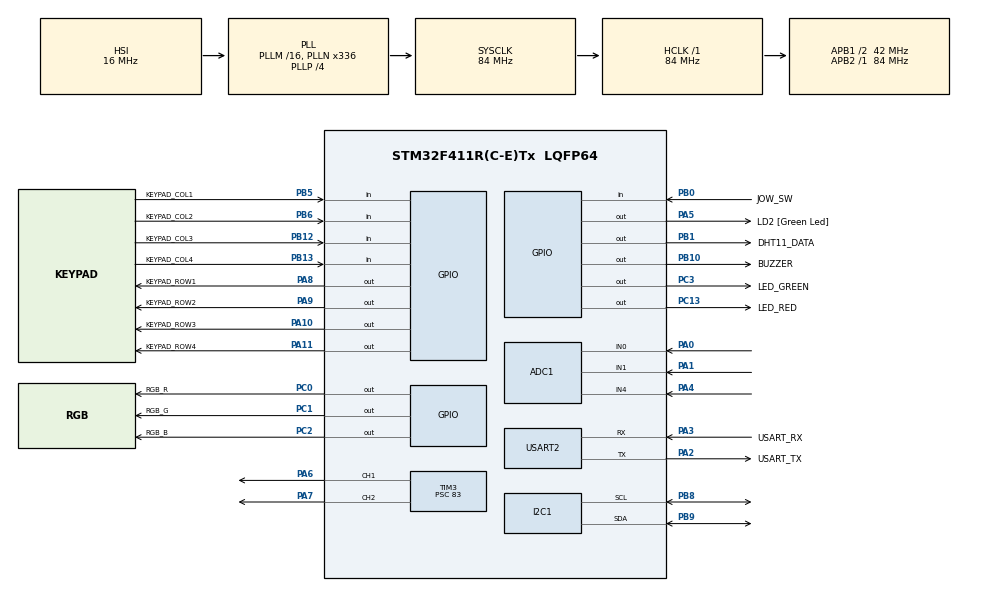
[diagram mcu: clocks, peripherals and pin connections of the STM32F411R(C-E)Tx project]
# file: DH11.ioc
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ADC1.Channel-0\#ChannelRegularConversion=ADC_CHANNEL_0
ADC1.Channel-1\#ChannelRegularConversion=ADC_CHANNEL_1
ADC1.Channel-2\#ChannelRegularConversion=ADC_CHANNEL_4
ADC1.Channel-3\#ChannelRegularConversion=ADC_CHANNEL_TEMPSENSOR
ADC1.ContinuousConvMode=ENABLE
ADC1.DMAContinuousRequests=ENABLE
ADC1.EOCSelection=ADC_EOC_SEQ_CONV
ADC1.NbrOfConversion=4
ADC1.NbrOfConversionFlag=1
ADC1.Rank-0\#ChannelRegularConversion=1
ADC1.Rank-1\#ChannelRegularConversion=2
ADC1.Rank-2\#ChannelRegularConversion=3
ADC1.Rank-3\#ChannelRegularConversion=4
ADC1.SamplingTime-0\#ChannelRegularConversion=ADC_SAMPLETIME_480CYCLES
ADC1.SamplingTime-1\#ChannelRegularConversion=ADC_SAMPLETIME_480CYCLES
ADC1.SamplingTime-2\#ChannelRegularConversion=ADC_SAMPLETIME_480CYCLES
ADC1.SamplingTime-3\#ChannelRegularConversion=ADC_SAMPLETIME_480CYCLES
ADC1.ScanConvMode=ENABLE
ADC1.master=1
Dma.ADC1.0.Direction=DMA_PERIPH_TO_MEMORY
Dma.ADC1.0.FIFOMode=DMA_FIFOMODE_DISABLE
Dma.ADC1.0.Instance=DMA2_Stream0
Dma.ADC1.0.MemDataAlignment=DMA_MDATAALIGN_HALFWORD
Dma.ADC1.0.MemInc=DMA_MINC_ENABLE
Dma.ADC1.0.Mode=DMA_CIRCULAR
Dma.ADC1.0.PeriphDataAlignment=DMA_PDATAALIGN_HALFWORD
Dma.ADC1.0.PeriphInc=DMA_PINC_DISABLE
Dma.ADC1.0.Priority=DMA_PRIORITY_LOW
Dma.Request0=ADC1
Mcu.Family=STM32F4
Mcu.Name=STM32F411R(C-E)Tx
Mcu.Package=LQFP64
NVIC.DMA2_Stream0_IRQn=true\:0\:0\:false\:false\:true\:false\:true\:true
NVIC.PriorityGroup=NVIC_PRIORITYGROUP_0
PA0-WKUP.Signal=ADCx_IN0
PA1.Signal=ADCx_IN1
PA10.GPIO_Label=KEYPAD_ROW3
PA10.Signal=GPIO_Output
PA11.GPIO_Label=KEYPAD_ROW4
PA11.Signal=GPIO_Output
PA13.GPIO_Label=TMS
PA13.Mode=Serial_Wire
PA13.Signal=SYS_JTMS-SWDIO
PA14.GPIO_Label=TCK
PA14.Mode=Serial_Wire
PA14.Signal=SYS_JTCK-SWCLK
PA2.GPIO_Label=USART_TX
PA2.Mode=Asynchronous
PA2.Signal=USART2_TX
PA3.GPIO_Label=USART_RX
PA3.Mode=Asynchronous
PA3.Signal=USART2_RX
PA4.Signal=ADCx_IN4
PA5.GPIO_Label=LD2 [Green Led]
PA5.Signal=GPIO_Output
PA6.Signal=S_TIM3_CH1
PA7.Signal=S_TIM3_CH2
PA8.GPIO_Label=KEYPAD_ROW1
PA8.Signal=GPIO_Output
PA9.GPIO_Label=KEYPAD_ROW2
PA9.Signal=GPIO_Output
PB0.GPIO_Label=JOW_SW
PB0.GPIO_PuPd=GPIO_PULLUP
PB0.Signal=GPIO_Input
PB1.GPIO_Label=DHT11_DATA
PB1.Signal=GPIO_Output
PB10.GPIO_Label=BUZZER
PB10.Signal=GPIO_Output
PB12.GPIO_Label=KEYPAD_COL3
PB12.GPIO_PuPd=GPIO_PULLUP
PB12.Signal=GPIO_Input
PB13.GPIO_Label=KEYPAD_COL4
PB13.GPIO_PuPd=GPIO_PULLUP
PB13.Signal=GPIO_Input
PB3.GPIO_Label=SWO
PB3.Signal=SYS_JTDO-SWO
PB5.GPIO_Label=KEYPAD_COL1
PB5.GPIO_PuPd=GPIO_PULLUP
PB5.Signal=GPIO_Input
PB6.GPIO_Label=KEYPAD_COL2
PB6.GPIO_PuPd=GPIO_PULLUP
PB6.Signal=GPIO_Input
PB8.Mode=I2C
PB8.Signal=I2C1_SCL
PB9.Mode=I2C
PB9.Signal=I2C1_SDA
PC0.GPIO_Label=RGB_R
PC0.Signal=GPIO_Output
PC1.GPIO_Label=RGB_G
PC1.Signal=GPIO_Output
PC13-ANTI_TAMP.GPIO_Label=LED_RED
PC13-ANTI_TAMP.Signal=GPIO_Output
PC2.GPIO_Label=RGB_B
PC2.Signal=GPIO_Output
PC3.GPIO_Label=LED_GREEN
PC3.Signal=GPIO_Output
PH0\ -\ OSC_IN.Mode=HSE-External-Clock-Source
PH0\ -\ OSC_IN.Signal=RCC_OSC_IN
PH1\ -\ OSC_OUT.Mode=HSE-External-Clock-Source
PH1\ -\ OSC_OUT.Signal=RCC_OSC_OUT
ProjectManager.HeapSize=0x200
ProjectManager.StackSize=0x400
ProjectManager.TargetToolchain=CMake
RCC.48MHZClocksFreq_Value=84000000
RCC.AHBFreq_Value=84000000
RCC.APB1CLKDivider=RCC_HCLK_DIV2
RCC.APB1Freq_Value=42000000
RCC.APB1TimFreq_Value=84000000
RCC.APB2Freq_Value=84000000
RCC.APB2TimFreq_Value=84000000
RCC.CortexFreq_Value=84000000
RCC.FLatency-AdvancedSettings=FLASH_LATENCY_2
RCC.HCLKFreq_Value=84000000
RCC.HSE_VALUE=8000000
RCC.HSI_VALUE=16000000
RCC.LSE_VALUE=32768
RCC.PLLN=336
RCC.PLLP=RCC_PLLP_DIV4
RCC.SYSCLKFreq_VALUE=84000000
RCC.SYSCLKSource=RCC_SYSCLKSOURCE_PLLCLK
RCC.VCOOutputFreq_Value=336000000
RTC.Date=27
RTC.Hours=9
RTC.Minutes=0
RTC.WeekDay=RTC_WEEKDAY_TUESDAY
RTC.Year=26
SH.ADCx_IN0.0=ADC1_IN0,IN0
SH.ADCx_IN1.0=ADC1_IN1,IN1
SH.ADCx_IN4.0=ADC1_IN4,IN4
SH.S_TIM3_CH1.0=TIM3_CH1,PWM Generation1 CH1
SH.S_TIM3_CH2.0=TIM3_CH2,PWM Generation2 CH2
TIM2.Period=65535
TIM2.Prescaler=83
TIM3.AutoReloadPreload=TIM_AUTORELOAD_PRELOAD_ENABLE
TIM3.Channel-PWM\ Generation1\ CH1=TIM_CHANNEL_1
TIM3.Channel-PWM\ Generation2\ CH2=TIM_CHANNEL_2
TIM3.Period=19999
TIM3.Prescaler=83
TIM3.Pulse-PWM\ Generation1\ CH1=1000
TIM3.Pulse-PWM\ Generation2\ CH2=1000
USART2.VirtualMode=VM_ASYNC
VP_ADC1_TempSens_Input.Mode=IN-TempSens
VP_RTC_VS_RTC_Activate.Mode=RTC_Enabled
VP_RTC_VS_RTC_Calendar.Mode=RTC_Calendar
VP_TIM2_VS_ClockSourceINT.Mode=Internal
VP_TIM3_VS_ClockSourceINT.Mode=Internal
board=NUCLEO-F411RE

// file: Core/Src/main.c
/* USER CODE BEGIN Header */
/**
 ******************************************************************************
 * @file           : main.c
 * @brief          : Main program body
 ******************************************************************************
 * @attention
 *
 * Copyright (c) 2026 STMicroelectronics.
 * All rights reserved.
 *
 * This software is licensed under terms that can be found in the LICENSE file
 * in the root directory of this software component.
 * If no LICENSE file comes with this software, it is provided AS-IS.
 *
 ******************************************************************************
 */
/* USER CODE END Header */
#include "main.h"
#include "adc.h"
#include "dma.h"
#include "i2c.h"
#include "rtc.h"
#include "tim.h"
#include "usart.h"
#include "gpio.h"

/* USER CODE BEGIN Includes */
#include "ap.h"
#include <stdio.h>
/* USER CODE END Includes */

void SystemClock_Config(void);
/* USER CODE BEGIN PFP */
#ifdef __GNUC__
#define PUTCHAR_PROTOTYPE int __io_putchar(int ch)
#else
#define PUTCHAR_PROTOTYPE int fputc(int ch, FILE *f)
#endif

PUTCHAR_PROTOTYPE {
  HAL_UART_Transmit(&huart2, (uint8_t *)&ch, 1, 0xFFFF);
  return ch;
}
/* USER CODE END PFP */

int main(void)
{

  /* MCU Configuration--------------------------------------------------------*/

  /* Reset of all peripherals, Initializes the Flash interface and the Systick. */
  HAL_Init();

  /* Configure the system clock */
  SystemClock_Config();

  /* Initialize all configured peripherals */
  MX_GPIO_Init();
  MX_DMA_Init();
  MX_USART2_UART_Init();
  MX_I2C1_Init();
  MX_ADC1_Init();
  MX_RTC_Init();
  MX_TIM2_Init();
  MX_TIM3_Init();
  /* USER CODE BEGIN 2 */
  // hwInit();
  apInit();
  apMain();
  /* USER CODE END 2 */

  /* Infinite loop */
  while (1) {

  }
}

void SystemClock_Config(void)
{
  RCC_OscInitTypeDef RCC_OscInitStruct = {0};
  RCC_ClkInitTypeDef RCC_ClkInitStruct = {0};

  /** Configure the main internal regulator output voltage
  */
  __HAL_RCC_PWR_CLK_ENABLE();
  __HAL_PWR_VOLTAGESCALING_CONFIG(PWR_REGULATOR_VOLTAGE_SCALE1);

  /** Initializes the RCC Oscillators according to the specified parameters
  * in the RCC_OscInitTypeDef structure.
  */
  RCC_OscInitStruct.OscillatorType = RCC_OSCILLATORTYPE_HSI|RCC_OSCILLATORTYPE_LSI;
  RCC_OscInitStruct.HSIState = RCC_HSI_ON;
  RCC_OscInitStruct.HSICalibrationValue = RCC_HSICALIBRATION_DEFAULT;
  RCC_OscInitStruct.LSIState = RCC_LSI_ON;
  RCC_OscInitStruct.PLL.PLLState = RCC_PLL_ON;
  RCC_OscInitStruct.PLL.PLLSource = RCC_PLLSOURCE_HSI;
  RCC_OscInitStruct.PLL.PLLM = 16;
  RCC_OscInitStruct.PLL.PLLN = 336;
  RCC_OscInitStruct.PLL.PLLP = RCC_PLLP_DIV4;
  RCC_OscInitStruct.PLL.PLLQ = 4;
  if (HAL_RCC_OscConfig(&RCC_OscInitStruct) != HAL_OK)
  {
    Error_Handler();
  }

  /** Initializes the CPU, AHB and APB buses clocks
  */
  RCC_ClkInitStruct.ClockType = RCC_CLOCKTYPE_HCLK|RCC_CLOCKTYPE_SYSCLK
                              |RCC_CLOCKTYPE_PCLK1|RCC_CLOCKTYPE_PCLK2;
  RCC_ClkInitStruct.SYSCLKSource = RCC_SYSCLKSOURCE_PLLCLK;
  RCC_ClkInitStruct.AHBCLKDivider = RCC_SYSCLK_DIV1;
  RCC_ClkInitStruct.APB1CLKDivider = RCC_HCLK_DIV2;
  RCC_ClkInitStruct.APB2CLKDivider = RCC_HCLK_DIV1;

  if (HAL_RCC_ClockConfig(&RCC_ClkInitStruct, FLASH_LATENCY_2) != HAL_OK)
  {
    Error_Handler();
  }
}

void Error_Handler(void)
{
  __disable_irq();
  while (1) {
  }
}
#ifdef USE_FULL_ASSERT
/**
  * @brief  Reports the name of the source file and the source line number
  *         where the assert_param error has occurred.
  * @param  file: pointer to the source file name
  * @param  line: assert_param error line source number
  * @retval None
  */
void assert_failed(uint8_t *file, uint32_t line)
{
  /* USER CODE BEGIN 6 */
  /* User can add his own implementation to report the file name and line
     number, ex: printf("Wrong parameters value: file %s on line %d\r\n", file,
     line) */
  /* USER CODE END 6 */
}
#endif /* USE_FULL_ASSERT */
